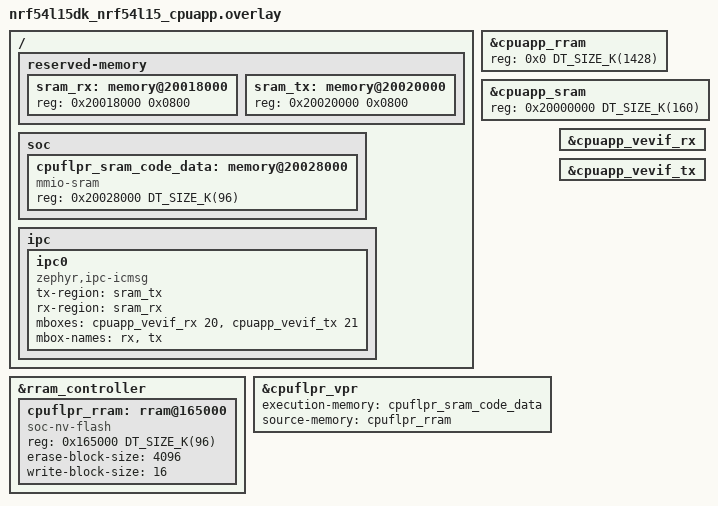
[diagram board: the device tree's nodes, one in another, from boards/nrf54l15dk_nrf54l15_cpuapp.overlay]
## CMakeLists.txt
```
# SPDX-License-Identifier: Apache-2.0
# SPDX-FileCopyrightText: Copyright (c) 2026 N-iX

cmake_minimum_required(VERSION 3.20.0)
find_package(Zephyr REQUIRED HINTS $ENV{ZEPHYR_BASE})
project(dali_controller)

target_sources(app PRIVATE
  src/cpuapp_heartbeat.c
  src/main.c
)

target_sources_ifdef(CONFIG_DALI_CPU_LOAD_REPORTING app PRIVATE
  src/cpu_load_reporter.c
)

target_sources_ifdef(CONFIG_DALI_BLE_LOAD app PRIVATE
  src/ble_load.c
)
```

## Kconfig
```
# SPDX-License-Identifier: Apache-2.0
# SPDX-FileCopyrightText: Copyright (c) 2026 N-iX

source "Kconfig.zephyr"

menu "DALI controller diagnostics"

config DALI_CPU_LOAD_REPORTING
	bool "Periodic CPU load reporting"
	depends on CPU_LOAD
	help
	  Report the CPUAPP non-idle time periodically. This diagnostic option
	  is enabled through the DALI_CPU_LOAD_MEASUREMENT sysbuild option. It
	  reports total core activity, including interrupt handling, but does
	  not attribute load to individual threads or DALI operations.

config DALI_CPU_LOAD_REPORT_INTERVAL_S
	int "CPU load report interval in seconds"
	depends on DALI_CPU_LOAD_REPORTING
	range 1 3600
	default 10
	help
	  Time window used to calculate and report CPUAPP load.

config DALI_BLE_LOAD
	bool "BLE advertising workload"
	depends on BT && BT_BROADCASTER
	help
	  Start non-connectable BLE advertising with a 20 ms interval before
	  DALI setup. This diagnostic workload creates CPUAPP radio activity
	  while the CPUFLPR configures the DALI network. It is intended for
	  comparing DALI timing with and without an active BLE controller.

config DALI_IPC_LATENCY_MEASUREMENT
	bool "IPC latency GPIO measurement"
	depends on GPIO
	help
	  Drive LED2 high while a CPUAPP DALI IPC request is outstanding and
	  return it low in the response callback. CPUFLPR drives LED3 high when
	  it receives the request and low immediately before sending the response.
	  The two markers measure each direction of real DALI API requests. This
	  diagnostic option is enabled through the
	  DALI_IPC_LATENCY_MEASUREMENT sysbuild option.

endmenu
```

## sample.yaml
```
# SPDX-License-Identifier: Apache-2.0

sample:
  name: DALI nRF54 controller
  description: CPUAPP controller sample that drives the FLPR DALI API over IPC.
common:
  platform_allow:
    - nrf54l15dk/nrf54l15/cpuapp
  tags:
    - dali
    - ipc
tests:
  sample.dali_nrf54.controller:
    build_only: true
```

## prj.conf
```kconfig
CONFIG_CONSOLE=y
CONFIG_PRINTK=y
CONFIG_SERIAL=y
CONFIG_UART_CONSOLE=y
CONFIG_LOG=y
CONFIG_LOG_DEFAULT_LEVEL=3
CONFIG_LOG_MODE_IMMEDIATE=y
CONFIG_GPIO=y
CONFIG_MBOX=y
CONFIG_IPC_SERVICE=y
CONFIG_IPC_SERVICE_LOG_LEVEL_INF=y
CONFIG_DALI_NRF54=y
```

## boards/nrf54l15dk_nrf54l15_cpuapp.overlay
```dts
// SPDX-License-Identifier: Apache-2.0
// SPDX-FileCopyrightText: Copyright (c) 2026 N-iX

/ {
	reserved-memory {
		#address-cells = <1>;
		#size-cells = <1>;

		sram_rx: memory@20018000 {
			reg = <0x20018000 0x0800>;
		};

		sram_tx: memory@20020000 {
			reg = <0x20020000 0x0800>;
		};
	};

	soc {
		cpuflpr_sram_code_data: memory@20028000 {
			compatible = "mmio-sram";
			reg = <0x20028000 DT_SIZE_K(96)>;
			#address-cells = <1>;
			#size-cells = <1>;
			ranges = <0x0 0x20028000 0x18000>;
		};
	};

	ipc {
		ipc0: ipc0 {
			compatible = "zephyr,ipc-icmsg";
			tx-region = <&sram_tx>;
			rx-region = <&sram_rx>;
			mboxes = <&cpuapp_vevif_rx 20>, <&cpuapp_vevif_tx 21>;
			mbox-names = "rx", "tx";
			status = "okay";
		};
	};
};

&cpuapp_rram {
	/* nRF54L15 has 1524 KB of usable RRAM; the FLPR image below takes the
	 * top 96 KB (0x165000-0x17D000), so CPUAPP gets the remaining 1428 KB.
	 * Mirrors Nordic's own nordic-flpr snippet 1:1 (see
	 * zephyr/snippets/nordic/nordic-flpr/soc/nrf54l15_cpuapp.overlay).
	 */
	reg = <0x0 DT_SIZE_K(1428)>;
	ranges = <0x0 0x0 DT_SIZE_K(1428)>;

	/delete-node/ partitions;
};

&rram_controller {
	cpuflpr_rram: rram@165000 {
		compatible = "soc-nv-flash";
		reg = <0x165000 DT_SIZE_K(96)>;
		ranges = <0x0 0x165000 DT_SIZE_K(96)>;
		erase-block-size = <4096>;
		write-block-size = <16>;
		#address-cells = <1>;
		#size-cells = <1>;
	};
};

&cpuapp_sram {
	reg = <0x20000000 DT_SIZE_K(160)>;
	ranges = <0x0 0x20000000 0x28000>;
};

&cpuflpr_vpr {
	status = "okay";
	execution-memory = <&cpuflpr_sram_code_data>;
	source-memory = <&cpuflpr_rram>;
};

&cpuapp_vevif_rx {
	status = "okay";
};

&cpuapp_vevif_tx {
	status = "okay";
};

#define WITH_FLPR_PARTITIONS
#include <vendor/nordic/nrf54l15_cpuapp_partition.dtsi>
```

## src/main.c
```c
// SPDX-License-Identifier: Apache-2.0
// SPDX-FileCopyrightText: Copyright (c) 2026 N-iX

#include <errno.h>
#include <stdbool.h>
#include <stdint.h>

#include <zephyr/devicetree.h>
#include <zephyr/drivers/gpio.h>
#include <zephyr/kernel.h>
#include <zephyr/logging/log.h>

#include <dali/dali_api.h>

#if defined(CONFIG_DALI_BLE_LOAD)
#include "ble_load.h"
#endif
#include "cpuapp_heartbeat.h"
#if defined(CONFIG_DALI_CPU_LOAD_REPORTING)
#include "cpu_load_reporter.h"
#endif

LOG_MODULE_REGISTER(dali_controller, LOG_LEVEL_INF);

#define DALI_CONTROLLER_LEVEL_MAX             0xFEU
#define DALI_CONTROLLER_LEVEL_STEP_20_PERCENT 51U
#define DALI_CONTROLLER_POLL_MS               50U
#define DALI_CONTROLLER_DEBOUNCE_MS           100U

#define BUTTON0_NODE DT_ALIAS(sw0)
#define BUTTON1_NODE DT_ALIAS(sw1)
#define BUTTON2_NODE DT_ALIAS(sw2)
#define BUTTON3_NODE DT_ALIAS(sw3)

#if !DT_NODE_HAS_STATUS_OKAY(BUTTON0_NODE)
#error "Unsupported board: sw0 devicetree alias is not defined"
#endif

#if !DT_NODE_HAS_STATUS_OKAY(BUTTON1_NODE)
#error "Unsupported board: sw1 devicetree alias is not defined"
#endif

#if !DT_NODE_HAS_STATUS_OKAY(BUTTON2_NODE)
#error "Unsupported board: sw2 devicetree alias is not defined"
#endif

#if !DT_NODE_HAS_STATUS_OKAY(BUTTON3_NODE)
#error "Unsupported board: sw3 devicetree alias is not defined"
#endif

struct dali_controller_button {
	const struct gpio_dt_spec *spec;
	bool sampled_pressed;
	bool stable_pressed;
	int64_t debounce_deadline_ms;
};

enum dali_controller_mode {
	DALI_CONTROLLER_MODE_BROADCAST = 0,
	DALI_CONTROLLER_MODE_ADDRESSED_GROUPS,
};

enum dali_controller_group {
	DALI_CONTROLLER_GROUP_EVEN = 0,
	DALI_CONTROLLER_GROUP_ODD,
	DALI_CONTROLLER_GROUP_COUNT,
};

static const struct gpio_dt_spec button0 =
	GPIO_DT_SPEC_GET(BUTTON0_NODE, gpios);
static const struct gpio_dt_spec button1 =
	GPIO_DT_SPEC_GET(BUTTON1_NODE, gpios);
static const struct gpio_dt_spec button2 =
	GPIO_DT_SPEC_GET(BUTTON2_NODE, gpios);
static const struct gpio_dt_spec button3 =
	GPIO_DT_SPEC_GET(BUTTON3_NODE, gpios);

static struct dali_api_discovery_result dali_discovery;
static enum dali_controller_mode dali_controller_mode;
static uint8_t dali_broadcast_level = DALI_CONTROLLER_LEVEL_MAX;
static uint8_t dali_group_levels[DALI_CONTROLLER_GROUP_COUNT] = {
	DALI_CONTROLLER_LEVEL_MAX,
	DALI_CONTROLLER_LEVEL_MAX,
};

static int dali_controller_for_each_short(int (*fn)(uint8_t short_address))
{
	uint32_t i;

	for (i = 0; i < dali_discovery.count; i++) {
		int err = fn(dali_discovery.devices[i].short_address);

		if (err != 0) {
			return err;
		}
	}

	return 0;
}

static const char *dali_controller_group_name(enum dali_controller_group group)
{
	switch (group) {
	case DALI_CONTROLLER_GROUP_EVEN:
		return "even";
	case DALI_CONTROLLER_GROUP_ODD:
		return "odd";
	default:
		return "unknown";
	}
}

static bool dali_controller_short_in_group(uint8_t short_address,
					   enum dali_controller_group group)
{
	bool is_even = (short_address & 0x01U) == 0U;

	return (group == DALI_CONTROLLER_GROUP_EVEN) ? is_even : !is_even;
}

static uint32_t
dali_controller_group_device_count(enum dali_controller_group group)
{
	uint32_t count = 0U;
	uint32_t i;

	for (i = 0; i < dali_discovery.count; i++) {
		if (dali_controller_short_in_group(
			    dali_discovery.devices[i].short_address, group)) {
			count++;
		}
	}

	return count;
}

static int dali_controller_group_first_short(enum dali_controller_group group,
					     uint8_t *short_address)
{
	uint32_t i;

	for (i = 0; i < dali_discovery.count; i++) {
		uint8_t candidate = dali_discovery.devices[i].short_address;

		if (dali_controller_short_in_group(candidate, group)) {
			*short_address = candidate;
			return 0;
		}
	}

	return -ENOENT;
}

static int dali_controller_off_all(void)
{
	int err;

	if (dali_controller_mode == DALI_CONTROLLER_MODE_BROADCAST) {
		err = dali_api_off_broadcast();
		LOG_INF("off mode=broadcast rc=%d", err);
	} else {
		err = dali_controller_for_each_short(dali_api_off_short);
		LOG_INF("off mode=addressed count=%u rc=%d",
			dali_discovery.count, err);
	}

	if (err == 0) {
		dali_broadcast_level = 0U;
	}

	return err;
}

static int dali_controller_on_all(void)
{
	int err;

	if (dali_controller_mode == DALI_CONTROLLER_MODE_BROADCAST) {
		err = dali_api_recall_max_broadcast();
		LOG_INF("on mode=broadcast rc=%d", err);
	} else {
		err = dali_controller_for_each_short(dali_api_recall_max_short);
		LOG_INF("on mode=addressed count=%u rc=%d",
			dali_discovery.count, err);
	}

	if (err == 0) {
		dali_broadcast_level = DALI_CONTROLLER_LEVEL_MAX;
	}

	return err;
}

static int dali_controller_set_all_level(uint8_t level)
{
	int err;

	if (dali_controller_mode == DALI_CONTROLLER_MODE_BROADCAST) {
		err = dali_api_set_level_broadcast(level);
		LOG_INF("set_level mode=broadcast level=%u rc=%d", level, err);
	} else {
		uint32_t i;

		err = 0;
		for (i = 0; i < dali_discovery.count; i++) {
			err = dali_api_set_level_short(
				dali_discovery.devices[i].short_address, level);
			if (err != 0) {
				break;
			}
		}

		LOG_INF("set_level mode=addressed count=%u level=%u rc=%d",
			dali_discovery.count, level, err);
	}

	if (err == 0) {
		dali_broadcast_level = level;
	}

	return err;
}

static int dali_controller_group_set_level(enum dali_controller_group group,
					   uint8_t level)
{
	uint32_t count = 0U;
	uint32_t i;
	int err = 0;

	for (i = 0; i < dali_discovery.count; i++) {
		uint8_t short_address = dali_discovery.devices[i].short_address;

		if (!dali_controller_short_in_group(short_address, group)) {
			continue;
		}

		err = dali_api_set_level_short(short_address, level);
		if (err != 0) {
			break;
		}

		count++;
	}

	if (count == 0U) {
		LOG_INF("set_level group=%s empty, skipping",
			dali_controller_group_name(group));
		return 0;
	}

	if (err == 0) {
		dali_group_levels[group] = level;
	}

	LOG_INF("set_level group=%s count=%u level=%u rc=%d",
		dali_controller_group_name(group), count, level, err);
	return err;
}

static uint8_t dali_controller_level_add_wrap(uint8_t level)
{
	uint16_t next = (uint16_t)level + DALI_CONTROLLER_LEVEL_STEP_20_PERCENT;

	if (level >= DALI_CONTROLLER_LEVEL_MAX) {
		return 0U;
	}

	if (next > DALI_CONTROLLER_LEVEL_MAX) {
		return DALI_CONTROLLER_LEVEL_MAX;
	}

	return (uint8_t)next;
}

static uint8_t dali_controller_level_down(uint8_t level)
{
	if (level <= DALI_CONTROLLER_LEVEL_STEP_20_PERCENT) {
		return 0U;
	}

	return level - DALI_CONTROLLER_LEVEL_STEP_20_PERCENT;
}

static uint8_t dali_controller_level_up(uint8_t level)
{
	uint16_t next = (uint16_t)level + DALI_CONTROLLER_LEVEL_STEP_20_PERCENT;

	if (next > DALI_CONTROLLER_LEVEL_MAX) {
		return DALI_CONTROLLER_LEVEL_MAX;
	}

	return (uint8_t)next;
}

static int dali_controller_toggle_group(enum dali_controller_group group)
{
	uint8_t next_level;
	int err;

	next_level = (dali_group_levels[group] > 0U)
			     ? 0U
			     : DALI_CONTROLLER_LEVEL_MAX;
	err = dali_controller_group_set_level(group, next_level);
	LOG_INF("toggle group=%s level=%u rc=%d",
		dali_controller_group_name(group), next_level, err);
	return err;
}

static int dali_controller_step_group(enum dali_controller_group group)
{
	uint8_t next_level =
		dali_controller_level_add_wrap(dali_group_levels[group]);
	int err = dali_controller_group_set_level(group, next_level);

	LOG_INF("step group=%s level=%u rc=%d",
		dali_controller_group_name(group), next_level, err);
	return err;
}

static int dali_controller_configure_button(const struct gpio_dt_spec *button)
{
	int err;

	if (!gpio_is_ready_dt(button)) {
		return -ENODEV;
	}

	err = gpio_pin_configure_dt(button, GPIO_INPUT);
	if (err != 0) {
		return err;
	}

	return 0;
}

static bool dali_controller_button_pressed(const struct gpio_dt_spec *button)
{
	int value = gpio_pin_get_dt(button);

	return value > 0;
}

static int dali_controller_handle_button_action(size_t button_index)
{
	if (dali_controller_mode == DALI_CONTROLLER_MODE_ADDRESSED_GROUPS) {
		switch (button_index) {
		case 0:
			return dali_controller_toggle_group(
				DALI_CONTROLLER_GROUP_EVEN);
		case 1:
			return dali_controller_toggle_group(
				DALI_CONTROLLER_GROUP_ODD);
		case 2:
			return dali_controller_step_group(
				DALI_CONTROLLER_GROUP_EVEN);
		case 3:
			return dali_controller_step_group(
				DALI_CONTROLLER_GROUP_ODD);
		default:
			return -EINVAL;
		}
	}

	switch (button_index) {
	case 0:
		return dali_controller_off_all();
	case 1:
		return dali_controller_on_all();
	case 2:
		return dali_controller_set_all_level(
			dali_controller_level_down(dali_broadcast_level));
	case 3:
		return dali_controller_set_all_level(
			dali_controller_level_up(dali_broadcast_level));
	default:
		return -EINVAL;
	}
}

static void
dali_controller_handle_buttons(struct dali_controller_button *buttons,
			       size_t count)
{
	int64_t now_ms = k_uptime_get();
	size_t i;

	for (i = 0; i < count; i++) {
		bool pressed = dali_controller_button_pressed(buttons[i].spec);

		if (pressed != buttons[i].sampled_pressed) {
			buttons[i].sampled_pressed = pressed;
			buttons[i].debounce_deadline_ms =
				now_ms + DALI_CONTROLLER_DEBOUNCE_MS;
			continue;
		}

		if (buttons[i].stable_pressed == buttons[i].sampled_pressed) {
			continue;
		}

		if (now_ms < buttons[i].debounce_deadline_ms) {
			continue;
		}

		buttons[i].stable_pressed = buttons[i].sampled_pressed;
		if (buttons[i].stable_pressed) {
			int err = dali_controller_handle_button_action(i);

			if (err != 0) {
				LOG_ERR("button%u action failed -> %d",
					(unsigned int)i, err);
			}
		}
	}
}

int main(void)
{
	int err;
	struct dali_controller_button buttons[] = {
		{.spec = &button0},
		{.spec = &button1},
		{.spec = &button2},
		{.spec = &button3},
	};
	size_t i;

	LOG_INF("starting CPUAPP DALI controller");

	err = cpuapp_heartbeat_init();
	if (err != 0) {
		LOG_ERR("cpuapp_heartbeat_init failed -> %d", err);
		return err;
	}

	for (i = 0; i < ARRAY_SIZE(buttons); i++) {
		err = dali_controller_configure_button(buttons[i].spec);
		if (err != 0) {
			LOG_ERR("button%u init failed -> %d", (unsigned int)i,
				err);
			return err;
		}
	}

#if defined(CONFIG_DALI_BLE_LOAD)
	err = dali_ble_load_start();
	if (err != 0) {
		LOG_ERR("BLE load start failed -> %d", err);
		return err;
	}
#endif

	err = dali_api_init();
	if (err != 0) {
		LOG_ERR("dali_api_init failed -> %d", err);
		return err;
	}

	k_sleep(K_SECONDS(1));

#if defined(CONFIG_DALI_CPU_LOAD_REPORTING)
	dali_cpu_load_reporter_reset();
#endif
	err = dali_api_discover(&dali_discovery);
	if (err == 0 && dali_discovery.count > 0U) {
		enum dali_controller_group group;

		dali_controller_mode = DALI_CONTROLLER_MODE_ADDRESSED_GROUPS;
		LOG_INF("discovered %u devices", dali_discovery.count);
		LOG_INF("%s", "addressed even/odd groups");

		for (group = DALI_CONTROLLER_GROUP_EVEN;
		     group < DALI_CONTROLLER_GROUP_COUNT; group++) {
			uint8_t short_address;
			uint8_t level = DALI_CONTROLLER_LEVEL_MAX;
			uint32_t count =
				dali_controller_group_device_count(group);

			if (count == 0U) {
				dali_group_levels[group] =
					DALI_CONTROLLER_LEVEL_MAX;
				LOG_INF("group=%s has no devices",
					dali_controller_group_name(group));
				continue;
			}

			err = dali_controller_group_first_short(group,
								&short_address);
			if (err != 0) {
				dali_group_levels[group] =
					DALI_CONTROLLER_LEVEL_MAX;
				LOG_WRN("group=%s first lookup rc=%d",
					dali_controller_group_name(group), err);
				continue;
			}

			err = dali_api_query_actual_level_short(short_address,
								&level);
			if (err == 0) {
				dali_group_levels[group] = level;
			} else {
				dali_group_levels[group] =
					DALI_CONTROLLER_LEVEL_MAX;
				LOG_WRN("group=%s level query rc=%d, using max",
					dali_controller_group_name(group), err);
			}

			LOG_INF("group=%s count=%u short=0x%02x level=%u",
				dali_controller_group_name(group), count,
				short_address, dali_group_levels[group]);
		}
	} else {
		dali_controller_mode = DALI_CONTROLLER_MODE_BROADCAST;
		dali_discovery.count = 0U;
		dali_broadcast_level = DALI_CONTROLLER_LEVEL_MAX;
		if (err != 0) {
			LOG_WRN("broadcast fallback rc=%d", err);
		} else {
			LOG_WRN("%s", "no devices, broadcast fallback");
		}
	}

#if defined(CONFIG_DALI_CPU_LOAD_REPORTING)
	dali_cpu_load_reporter_report("network_setup");
	dali_cpu_load_reporter_start();
#endif

	while (true) {
		dali_controller_handle_buttons(buttons, ARRAY_SIZE(buttons));
		k_sleep(K_MSEC(DALI_CONTROLLER_POLL_MS));
	}
}
```

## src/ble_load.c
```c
// SPDX-License-Identifier: Apache-2.0
// SPDX-FileCopyrightText: Copyright (c) 2026 N-iX

#include <zephyr/bluetooth/bluetooth.h>
#include <zephyr/bluetooth/hci.h>
#include <zephyr/kernel.h>
#include <zephyr/logging/log.h>

#include "ble_load.h"

LOG_MODULE_REGISTER(dali_ble_load, LOG_LEVEL_INF);

#define DALI_BLE_LOAD_ADV_INTERVAL 0x0020U

static const struct bt_le_adv_param dali_ble_load_adv_param =
	BT_LE_ADV_PARAM_INIT(0, DALI_BLE_LOAD_ADV_INTERVAL,
			     DALI_BLE_LOAD_ADV_INTERVAL, NULL);
static const struct bt_data dali_ble_load_ad[] = {
	BT_DATA_BYTES(BT_DATA_FLAGS, BT_LE_AD_NO_BREDR),
	BT_DATA(BT_DATA_NAME_COMPLETE, CONFIG_BT_DEVICE_NAME,
		sizeof(CONFIG_BT_DEVICE_NAME) - 1U),
};

int dali_ble_load_start(void)
{
	int err;

	err = bt_enable(NULL);
	if (err != 0) {
		return err;
	}

	err = bt_le_adv_start(&dali_ble_load_adv_param, dali_ble_load_ad,
			      ARRAY_SIZE(dali_ble_load_ad), NULL, 0);
	if (err == 0) {
		LOG_INF("BLE load advertising interval=20ms");
	}

	return err;
}
```

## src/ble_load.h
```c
/* SPDX-License-Identifier: Apache-2.0 */
/* SPDX-FileCopyrightText: Copyright (c) 2026 N-iX */

#ifndef DALI_BLE_LOAD_H_
#define DALI_BLE_LOAD_H_

int dali_ble_load_start(void);

#endif /* DALI_BLE_LOAD_H_ */
```

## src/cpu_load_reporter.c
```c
// SPDX-License-Identifier: Apache-2.0
// SPDX-FileCopyrightText: Copyright (c) 2026 N-iX

#include <zephyr/debug/cpu_load.h>
#include <zephyr/kernel.h>
#include <zephyr/logging/log.h>

#include "cpu_load_reporter.h"

LOG_MODULE_REGISTER(dali_cpu_load, LOG_LEVEL_INF);

static void dali_cpu_load_report(struct k_work *work);

K_WORK_DELAYABLE_DEFINE(dali_cpu_load_work, dali_cpu_load_report);

void dali_cpu_load_reporter_reset(void)
{
	(void)cpu_load_get(true);
}

void dali_cpu_load_reporter_report(const char *window)
{
	int load_per_mille = cpu_load_get(true);

	if (load_per_mille < 0) {
		LOG_ERR("core=cpuapp load read failed rc=%d", load_per_mille);
	} else {
		LOG_INF("core=cpuapp load=%d.%d%% window=%s",
			load_per_mille / 10, load_per_mille % 10, window);
	}
}

static void dali_cpu_load_report(struct k_work *work)
{
	ARG_UNUSED(work);

	dali_cpu_load_reporter_report("periodic");

	(void)k_work_reschedule(
		&dali_cpu_load_work,
		K_SECONDS(CONFIG_DALI_CPU_LOAD_REPORT_INTERVAL_S));
}

void dali_cpu_load_reporter_start(void)
{
	dali_cpu_load_reporter_reset();
	(void)k_work_reschedule(
		&dali_cpu_load_work,
		K_SECONDS(CONFIG_DALI_CPU_LOAD_REPORT_INTERVAL_S));
}
```

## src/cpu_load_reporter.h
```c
/* SPDX-License-Identifier: Apache-2.0 */
/* SPDX-FileCopyrightText: Copyright (c) 2026 N-iX */

#ifndef DALI_CPU_LOAD_REPORTER_H_
#define DALI_CPU_LOAD_REPORTER_H_

void dali_cpu_load_reporter_start(void);
void dali_cpu_load_reporter_reset(void);
void dali_cpu_load_reporter_report(const char *window);

#endif /* DALI_CPU_LOAD_REPORTER_H_ */
```

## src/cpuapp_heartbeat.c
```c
// SPDX-License-Identifier: Apache-2.0

#include <errno.h>
#include <stdbool.h>

#include <zephyr/devicetree.h>
#include <zephyr/drivers/gpio.h>
#include <zephyr/kernel.h>
#include <zephyr/logging/log.h>

#include "cpuapp_heartbeat.h"

LOG_MODULE_REGISTER(cpuapp_heartbeat, LOG_LEVEL_INF);

#define CPUAPP_HEARTBEAT_NODE DT_ALIAS(led0)
#define CPUAPP_HEARTBEAT_MS   500U

#if !DT_NODE_HAS_STATUS_OKAY(CPUAPP_HEARTBEAT_NODE)
#error "Unsupported board: led0 devicetree alias is not defined"
#endif

static const struct gpio_dt_spec cpuapp_heartbeat_led =
	GPIO_DT_SPEC_GET(CPUAPP_HEARTBEAT_NODE, gpios);

K_THREAD_STACK_DEFINE(cpuapp_heartbeat_stack, 512);
static struct k_thread cpuapp_heartbeat_thread;
static bool cpuapp_heartbeat_started;

static void cpuapp_heartbeat_thread_fn(void *arg1, void *arg2, void *arg3)
{
	int err;
	bool state = false;

	ARG_UNUSED(arg1);
	ARG_UNUSED(arg2);
	ARG_UNUSED(arg3);

	while (true) {
		state = !state;
		err = gpio_pin_set_dt(&cpuapp_heartbeat_led, state);
		if (err != 0) {
			LOG_ERR("LED0 set failed -> %d", err);
			return;
		}

		k_sleep(K_MSEC(CPUAPP_HEARTBEAT_MS));
	}
}

int cpuapp_heartbeat_init(void)
{
	int err;

	if (cpuapp_heartbeat_started) {
		return 0;
	}

	if (!gpio_is_ready_dt(&cpuapp_heartbeat_led)) {
		return -ENODEV;
	}

	err = gpio_pin_configure_dt(&cpuapp_heartbeat_led,
				    GPIO_OUTPUT_INACTIVE);
	if (err != 0) {
		return err;
	}

	(void)k_thread_create(&cpuapp_heartbeat_thread, cpuapp_heartbeat_stack,
			      K_THREAD_STACK_SIZEOF(cpuapp_heartbeat_stack),
			      cpuapp_heartbeat_thread_fn, NULL, NULL, NULL, 7,
			      0, K_NO_WAIT);

	cpuapp_heartbeat_started = true;
	return 0;
}
```

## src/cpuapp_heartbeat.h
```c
/* SPDX-License-Identifier: Apache-2.0 */

#ifndef CPUAPP_HEARTBEAT_H_
#define CPUAPP_HEARTBEAT_H_

int cpuapp_heartbeat_init(void);

#endif /* CPUAPP_HEARTBEAT_H_ */
```
